# SN32F100 register map
Vendor: SONiX Technology Co., Ltd.; Series: SN32F100; File version: 1.3
CPU: CM0 r0p0, little endian, no MPU, no FPU, 2 interrupt priority bits
Registers are 32-bit, read-write, reset 0x0 unless marked. A register's access mark holds for its fields unless they carry their own. Offsets are from the block's base; [hi:lo] are bit positions.

## SN_DAC — Codec DAC Control Registers
Base 0x40065000
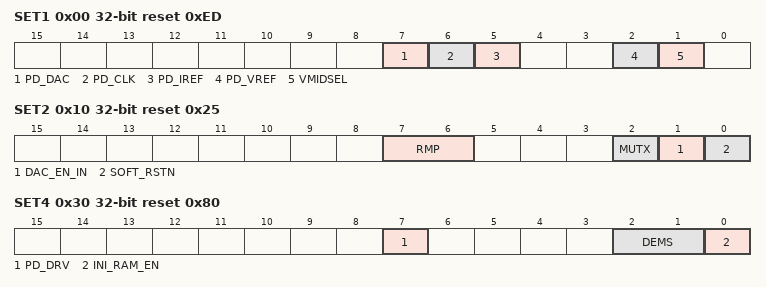
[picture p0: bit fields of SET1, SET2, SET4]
0x00 SET1 reset 0xED — Offset:0x000 DAC Setting 1 Register
  [7] PD_DAC — DAC Power-down enable
    0=Disable; 1=Enable
  [6] PD_CLK — CKGEN Power-down enable
    0=Disable; 1=Enable
  [5] PD_IREF — IREF Circuit Power-down enable
    0=Disable; 1=Enable
  [2] PD_VREF — VREF Circuit Power-down enable
    0=Disable; 1=Enable
  [1] VMIDSEL — Normal mode/Fast Start-up select
    0=Normal mode; 1=Fast Start-up mode
0x10 SET2 reset 0x25 — Offset:0x010 DAC Setting 2 Register
  [7:6] RMP — Attenuation ramp rate
    0=1*LRCK; 1=2*LRCK; 2=4*LRCK; 3=8*LRCK
  [2] MUTX — Mute ON/OFF
    0=Mute off; 1=Mute on
  [1] DAC_EN_IN — DAC Enable
    0=Disable; 1=Enable
  [0] SOFT_RSTN — Software reset digital circuit(one MCLK pulse trigger)
    0=Reset; 1=Not Reset
0x20 SET3 — Offset:0x020 DAC Setting 3 Register
  [7:0] VOL — DAC VOL setting
0x30 SET4 reset 0x80 — Offset:0x030 DAC Setting 4 Register
  [7] PD_DRV — Driver Power-down enable
    0=Disable; 1=Enable
  [2:1] DEMS — Select the DAC de-emphasis response curve
    1=De-emphasis for 48KHz; 2=De-emphasis for 44.1KHz; 3=De-emphasis for 32KHz
  [0] INI_RAM_EN — Initialize RAM enable
    0=Disable; 1=Enable
0x40 STATUS ro — Offset:0x040 DAC Status Register
  [0] Ini_RAM_Ready — Initialize RAM ready
    0=Not ready; 1=Ready

## SN_FLASH — FLASH Memory Control Registers
Base 0x40062000
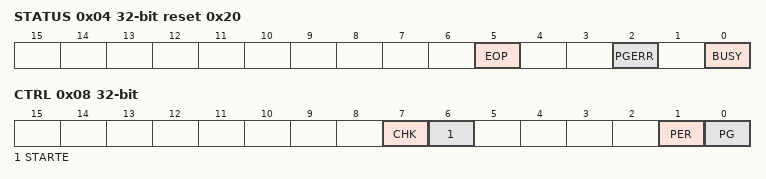
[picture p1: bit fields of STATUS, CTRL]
0x04 STATUS reset 0x20 — Offset:0x04 Flash Status Register
  [5] EOP — End of process flag
    0=Busy (Flash operation is not completed); 1=End (Flash operation is completed)
  [2] PGERR — Program error flag
    0=No error; 1=Program error (The address to be programmed contains a value different from 0xFFFF)
  [0] BUSY ro — Busy flag
    0=Idle (Flash operation is stopped.); 1=Busy (Flash operation is in process)
0x08 CTRL — Offset:0x08 Flash Control Register
  [7] CHK — Checksum calculation choosen
    0=Disable; 1=Enable (Trigger checksum calculation)
  [6] STARTE — Start erase operation
    0=Stop/Finish (Erase operation is finished.); 1=Start erase operation
  [1] PER — Page erase choosen
    0=Not chosen (Not choose page erase operation.); 1=Choose page erase operation
  [0] PG — Flash program choosen
    0=Not chosen (Not choose Flash program operation.); 1=Choose Flash program operation
0x0C DATA — Offset:0x0C Flash Data Register
0x10 ADDR — Offset:0x10 Flash Address Register
0x14 CHKSUM ro (reset mask 0xFFFF) — Offset:0x14 Flash Checksum Register

## SN_CMP — Comparator Control Register
Base 0x40066000
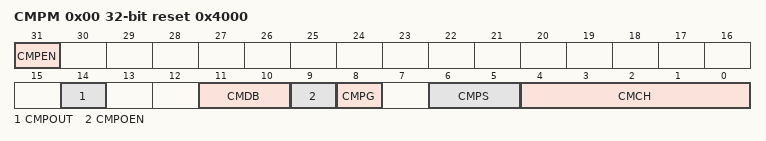
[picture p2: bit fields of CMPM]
0x00 CMPM reset 0x4000 — Offset:0x00 Comparator Control register
  [31] CMPEN — Comparator control bit
    0=Disable (P2[15:0], P3[7:0] are GPIO mode); 1=Enable (Comparator negative input pins are controlled by CMCH[4:0] bits)
  [14] CMPOUT — Comparator output flag bit (The comparator output status is "1" as comparator disable)
    0=Comparator internal reference voltage is less than CMPN voltage; 1=Comparator internal reference voltage is larger than CMPN voltage
  [11:10] CMDB — Comparator output debounce time select bit(TCHEN=1 is HCLK, TCHEN=0 is CMP_PCLK)
    0=1*CMP_PCLK (Comparator output debounce time = 1*CMP_PCLK); 1=2*CMP_PCLK (Comparator output debounce time = 2*CMP_PCLK); 2=3*CMP_PCLK (Comparator output debounce time = 3*CMP_PCLK); 3=No-debounce (Comparator output debounce time = 0)
  [9] CMPOEN — Comparator output pin control bit
    0=Disable (CMO pin is GPIO mode); 1=Enable comparator output pin (P3.8 pin exchanges to comparator output pin and GPIO function is isolated)
  [8] CMPG — Comparator interrupt trigger direction control bit
    0=Rising edge trigger (CMPP larger than CMPN or comparator internal reference voltage); 1=Falling edge trigger (CMPP less than CMPN or comparator internal reference voltage)
  [6:5] CMPS — Comparator positive input voltage control bit
    0=1/4*Vdd (Internal 1/4*Vdd and enable internal reference voltage generato); 1=1/2*Vdd (Internal 1/2*Vdd and enable internal reference voltage generator); 2=3/4*Vdd (Internal 3/4*Vdd and enable internal reference voltage generator); 3=3/4*Vdd (Internal 3/4*Vdd and enable internal reference voltage generator)
  [4:0] CMCH — Comparator negative input pin control bit (CMPEN must be "1")
    0=CM0 (Comparator negative input pin is P2.0); 1=CM1 (Comparator negative input pin is P2.1); 2=CM2 (Comparator negative input pin is P2.2); 3=CM3 (Comparator negative input pin is P2.3); 4=CM4 (Comparator negative input pin is P2.4); 5=CM5 (Comparator negative input pin is P2.5); 6=CM6 (Comparator negative input pin is P2.6); 7=CM7 (Comparator negative input pin is P2.7); 8=CM8 (Comparator negative input pin is P2.8); 9=CM9 (Comparator negative input pin is P2.9); 10=CM10 (Comparator negative input pin is P2.10); 11=CM11 (Comparator negative input pin is P2.11); 12=CM12 (Comparator negative input pin is P2.12); 13=CM13 (Comparator negative input pin is P2.13); 14=CM14 (Comparator negative input pin is P2.14); 15=CM15 (Comparator negative input pin is P2.15); 16=CM16 (Comparator negative input pin is P3.0); 17=CM17 (Comparator negative input pin is P3.1); 18=CM18 (Comparator negative input pin is P3.2); 19=CM19 (Comparator negative input pin is P3.3); 20=CM20 (Comparator negative input pin is P3.4); 21=CM21 (Comparator negative input pin is P3.5); 22=CM22 (Comparator negative input pin is P3.6); 23=CM23 (Comparator negative input pin is P3.7)
0x10 CMP_IE — Offset:0x10 Comparator Interrupt Enable register
  [0] CMPGIE — Comparator edge trigger interrupt enable (Comparator interrupt trigger direction refer to CMPG)
    0=Disable; 1=Enable
0x14 CMP_RIS ro — Offset:0x14 Comparator Interrupt Status register
  [0] CMPGIF — Comparator edge trigger interrupt flag
    0=No interrupt (Comparator edge trigger doesn't occur); 1=Met interrupt requirements (Comparator edge trigger occurs)
0x18 CMP_IC wo — Offset:0x18 Comparator Interrupt Clear register
  [0] CMPGIC — Comparator CMPGIF interrupt flag clear
    0=No effect; 1=Clear CMPGIF bit
